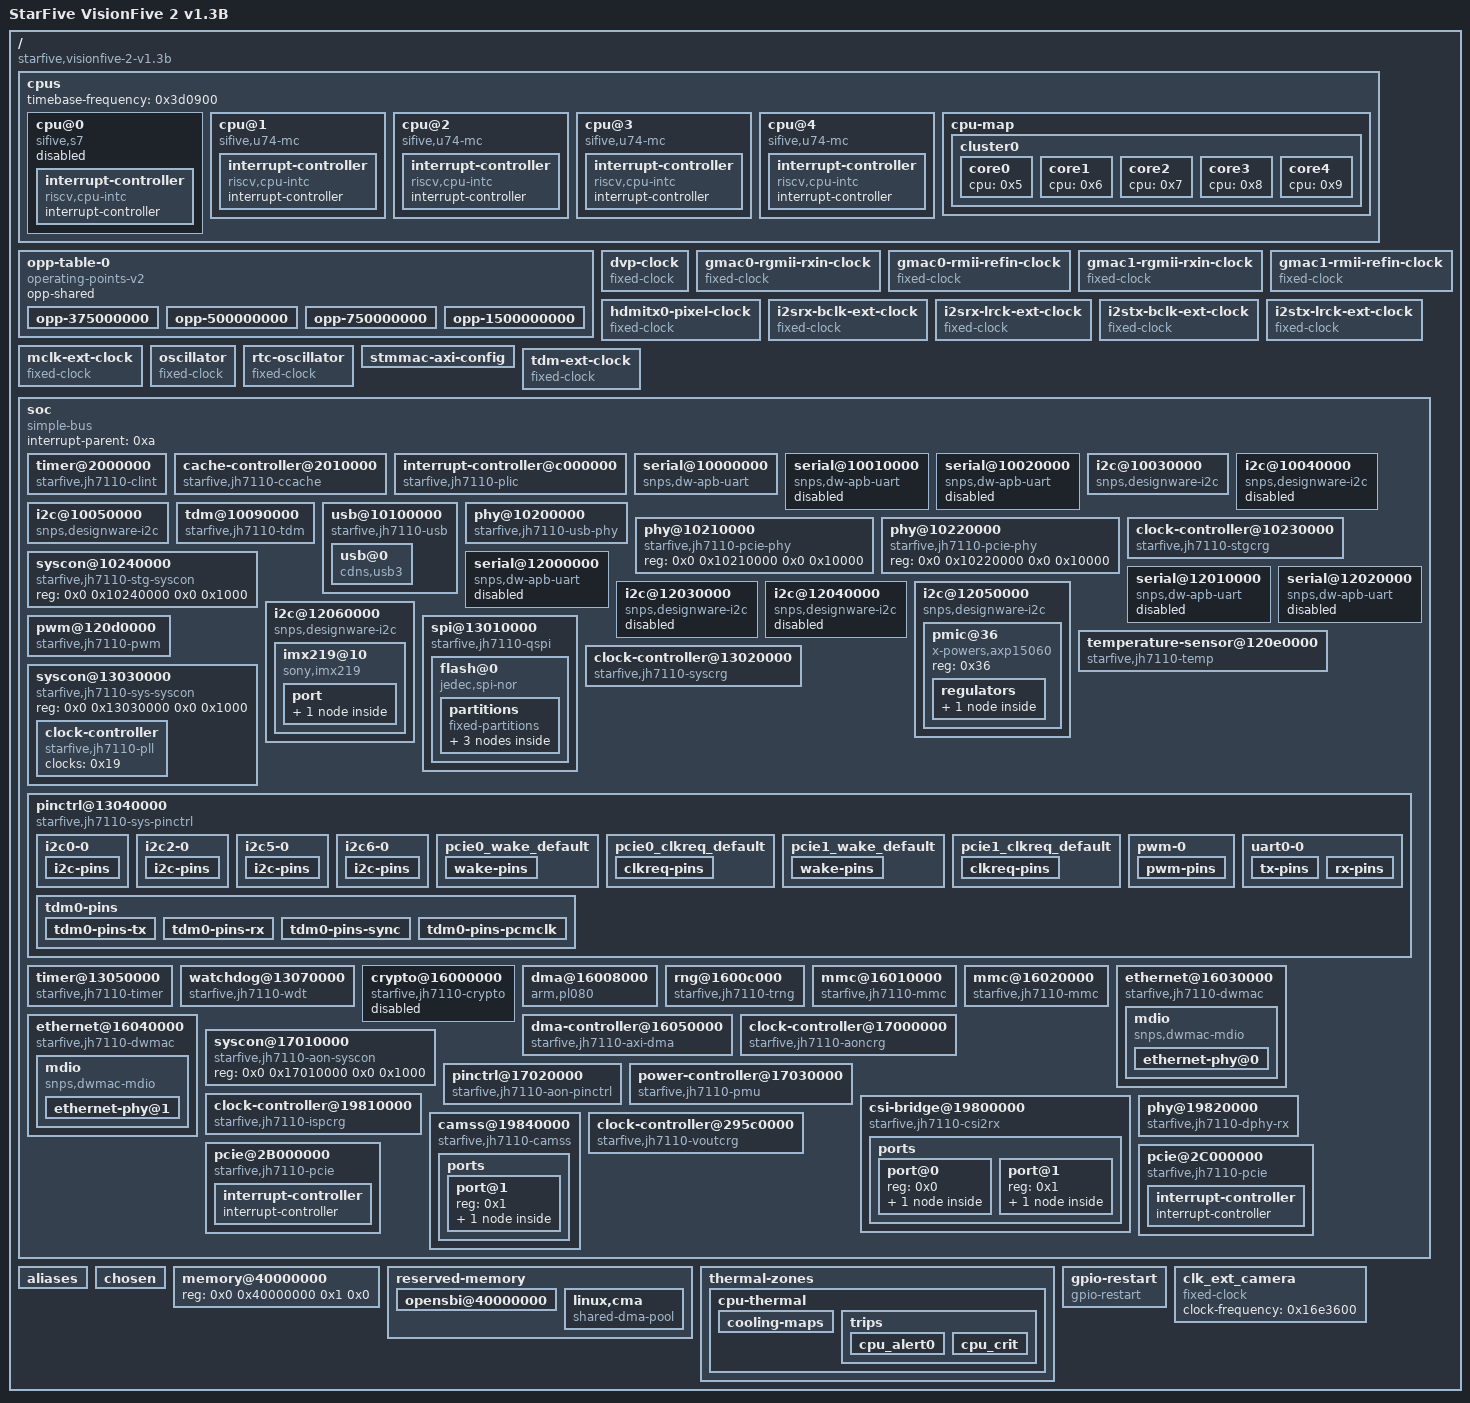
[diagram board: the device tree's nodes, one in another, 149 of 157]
/dts-v1/;

/  {

        serial-number = "VF7110B1-2253-D008E000-00003992";
        compatible = "starfive,visionfive-2-v1.3b", "starfive,jh7110";
        #address-cells = <0x2>;
        #size-cells = <0x2>;
        model = "StarFive VisionFive 2 v1.3B";
        cpus {

                #address-cells = <0x1>;
                #size-cells = <0x0>;
                timebase-frequency = <0x3d0900>;
                cpu@0 {

                        compatible = "sifive,s7", "riscv";
                        reg = <0x0>;
                        device_type = "cpu";
                        i-cache-block-size = <0x40>;
                        i-cache-sets = <0x40>;
                        i-cache-size = <0x4000>;
                        next-level-cache = <0x1>;
                        riscv,isa = "rv64imac_zba_zbb";
                        status = "disabled";
                        phandle = <0x5>;
                        interrupt-controller {

                                compatible = "riscv,cpu-intc";
                                interrupt-controller;
                                #interrupt-cells = <0x1>;
                                phandle = <0xb>;
                        };
                };
                cpu@1 {

                        compatible = "sifive,u74-mc", "riscv";
                        reg = <0x1>;
                        d-cache-block-size = <0x40>;
                        d-cache-sets = <0x40>;
                        d-cache-size = <0x8000>;
                        d-tlb-sets = <0x1>;
                        d-tlb-size = <0x28>;
                        device_type = "cpu";
                        i-cache-block-size = <0x40>;
                        i-cache-sets = <0x40>;
                        i-cache-size = <0x8000>;
                        i-tlb-sets = <0x1>;
                        i-tlb-size = <0x28>;
                        mmu-type = "riscv,sv39";
                        next-level-cache = <0x1>;
                        riscv,isa = "rv64imafdc_zba_zbb";
                        tlb-split;
                        operating-points-v2 = <0x2>;
                        clocks = <0x3 0x1>;
                        clock-names = "cpu";
                        cpu-supply = <0x4>;
                        phandle = <0x6>;
                        interrupt-controller {

                                compatible = "riscv,cpu-intc";
                                interrupt-controller;
                                #interrupt-cells = <0x1>;
                                phandle = <0xc>;
                        };
                };
                cpu@2 {

                        compatible = "sifive,u74-mc", "riscv";
                        reg = <0x2>;
                        d-cache-block-size = <0x40>;
                        d-cache-sets = <0x40>;
                        d-cache-size = <0x8000>;
                        d-tlb-sets = <0x1>;
                        d-tlb-size = <0x28>;
                        device_type = "cpu";
                        i-cache-block-size = <0x40>;
                        i-cache-sets = <0x40>;
                        i-cache-size = <0x8000>;
                        i-tlb-sets = <0x1>;
                        i-tlb-size = <0x28>;
                        mmu-type = "riscv,sv39";
                        next-level-cache = <0x1>;
                        riscv,isa = "rv64imafdc_zba_zbb";
                        tlb-split;
                        operating-points-v2 = <0x2>;
                        clocks = <0x3 0x1>;
                        clock-names = "cpu";
                        cpu-supply = <0x4>;
                        phandle = <0x7>;
                        interrupt-controller {

                                compatible = "riscv,cpu-intc";
                                interrupt-controller;
                                #interrupt-cells = <0x1>;
                                phandle = <0xd>;
                        };
                };
                cpu@3 {

                        compatible = "sifive,u74-mc", "riscv";
                        reg = <0x3>;
                        d-cache-block-size = <0x40>;
                        d-cache-sets = <0x40>;
                        d-cache-size = <0x8000>;
                        d-tlb-sets = <0x1>;
                        d-tlb-size = <0x28>;
                        device_type = "cpu";
                        i-cache-block-size = <0x40>;
                        i-cache-sets = <0x40>;
                        i-cache-size = <0x8000>;
                        i-tlb-sets = <0x1>;
                        i-tlb-size = <0x28>;
                        mmu-type = "riscv,sv39";
                        next-level-cache = <0x1>;
                        riscv,isa = "rv64imafdc_zba_zbb";
                        tlb-split;
                        operating-points-v2 = <0x2>;
                        clocks = <0x3 0x1>;
                        clock-names = "cpu";
                        cpu-supply = <0x4>;
                        phandle = <0x8>;
                        interrupt-controller {

                                compatible = "riscv,cpu-intc";
                                interrupt-controller;
                                #interrupt-cells = <0x1>;
                                phandle = <0xe>;
                        };
                };
                cpu@4 {

                        compatible = "sifive,u74-mc", "riscv";
                        reg = <0x4>;
                        d-cache-block-size = <0x40>;
                        d-cache-sets = <0x40>;
                        d-cache-size = <0x8000>;
                        d-tlb-sets = <0x1>;
                        d-tlb-size = <0x28>;
                        device_type = "cpu";
                        i-cache-block-size = <0x40>;
                        i-cache-sets = <0x40>;
                        i-cache-size = <0x8000>;
                        i-tlb-sets = <0x1>;
                        i-tlb-size = <0x28>;
                        mmu-type = "riscv,sv39";
                        next-level-cache = <0x1>;
                        riscv,isa = "rv64imafdc_zba_zbb";
                        tlb-split;
                        operating-points-v2 = <0x2>;
                        clocks = <0x3 0x1>;
                        clock-names = "cpu";
                        cpu-supply = <0x4>;
                        phandle = <0x9>;
                        interrupt-controller {

                                compatible = "riscv,cpu-intc";
                                interrupt-controller;
                                #interrupt-cells = <0x1>;
                                phandle = <0xf>;
                        };
                };
                cpu-map {

                        cluster0 {

                                core0 {

                                        cpu = <0x5>;
                                };
                                core1 {

                                        cpu = <0x6>;
                                };
                                core2 {

                                        cpu = <0x7>;
                                };
                                core3 {

                                        cpu = <0x8>;
                                };
                                core4 {

                                        cpu = <0x9>;
                                };
                        };
                };
        };
        opp-table-0 {

                compatible = "operating-points-v2";
                opp-shared;
                phandle = <0x2>;
                opp-375000000 {

                        opp-hz = <0x0 0x165a0bc0>;
                        opp-microvolt = <0xc3500>;
                };
                opp-500000000 {

                        opp-hz = <0x0 0x1dcd6500>;
                        opp-microvolt = <0xc3500>;
                };
                opp-750000000 {

                        opp-hz = <0x0 0x2cb41780>;
                        opp-microvolt = <0xc3500>;
                };
                opp-1500000000 {

                        opp-hz = <0x0 0x59682f00>;
                        opp-microvolt = <0xfde80>;
                };
        };
        dvp-clock {

                compatible = "fixed-clock";
                clock-output-names = "dvp_clk";
                #clock-cells = <0x0>;
                clock-frequency = <0x46cf710>;
                phandle = <0x36>;
        };
        gmac0-rgmii-rxin-clock {

                compatible = "fixed-clock";
                clock-output-names = "gmac0_rgmii_rxin";
                #clock-cells = <0x0>;
                clock-frequency = <0x7735940>;
                phandle = <0x30>;
        };
        gmac0-rmii-refin-clock {

                compatible = "fixed-clock";
                clock-output-names = "gmac0_rmii_refin";
                #clock-cells = <0x0>;
                clock-frequency = <0x2faf080>;
                phandle = <0x2f>;
        };
        gmac1-rgmii-rxin-clock {

                compatible = "fixed-clock";
                clock-output-names = "gmac1_rgmii_rxin";
                #clock-cells = <0x0>;
                clock-frequency = <0x7735940>;
                phandle = <0x21>;
        };
        gmac1-rmii-refin-clock {

                compatible = "fixed-clock";
                clock-output-names = "gmac1_rmii_refin";
                #clock-cells = <0x0>;
                clock-frequency = <0x2faf080>;
                phandle = <0x20>;
        };
        hdmitx0-pixel-clock {

                compatible = "fixed-clock";
                clock-output-names = "hdmitx0_pixelclk";
                #clock-cells = <0x0>;
                clock-frequency = <0x11b3dc40>;
                phandle = <0x39>;
        };
        i2srx-bclk-ext-clock {

                compatible = "fixed-clock";
                clock-output-names = "i2srx_bclk_ext";
                #clock-cells = <0x0>;
                clock-frequency = <0xbb8000>;
                phandle = <0x24>;
        };
        i2srx-lrck-ext-clock {

                compatible = "fixed-clock";
                clock-output-names = "i2srx_lrck_ext";
                #clock-cells = <0x0>;
                clock-frequency = <0x2ee00>;
                phandle = <0x25>;
        };
        i2stx-bclk-ext-clock {

                compatible = "fixed-clock";
                clock-output-names = "i2stx_bclk_ext";
                #clock-cells = <0x0>;
                clock-frequency = <0xbb8000>;
                phandle = <0x22>;
        };
        i2stx-lrck-ext-clock {

                compatible = "fixed-clock";
                clock-output-names = "i2stx_lrck_ext";
                #clock-cells = <0x0>;
                clock-frequency = <0x2ee00>;
                phandle = <0x23>;
        };
        mclk-ext-clock {

                compatible = "fixed-clock";
                clock-output-names = "mclk_ext";
                #clock-cells = <0x0>;
                clock-frequency = <0xbb8000>;
                phandle = <0x26>;
        };
        oscillator {

                compatible = "fixed-clock";
                clock-output-names = "osc";
                #clock-cells = <0x0>;
                clock-frequency = <0x16e3600>;
                phandle = <0x19>;
        };
        rtc-oscillator {

                compatible = "fixed-clock";
                clock-output-names = "rtc_osc";
                #clock-cells = <0x0>;
                clock-frequency = <0x8000>;
                phandle = <0x31>;
        };
        stmmac-axi-config {

                snps,lpi_en;
                snps,wr_osr_lmt = <0x4>;
                snps,rd_osr_lmt = <0x4>;
                snps,blen = <0x100 0x80 0x40 0x20 0x0 0x0 0x0>;
                phandle = <0x2b>;
        };
        tdm-ext-clock {

                compatible = "fixed-clock";
                clock-output-names = "tdm_ext";
                #clock-cells = <0x0>;
                clock-frequency = <0x2ee0000>;
                phandle = <0x13>;
        };
        soc {

                compatible = "simple-bus";
                interrupt-parent = <0xa>;
                #address-cells = <0x2>;
                #size-cells = <0x2>;
                ranges;
                timer@2000000 {

                        compatible = "starfive,jh7110-clint", "sifive,clint0";
                        reg = <0x0 0x2000000 0x0 0x10000>;
                        interrupts-extended = <0xb 0x3 0xb 0x7 0xc 0x3 0xc 0x7 0xd 0x3 0xd 0x7 0xe 0x3 0xe 0x7 0xf 0x3 0xf 0x7>;
                };
                cache-controller@2010000 {

                        compatible = "starfive,jh7110-ccache", "sifive,ccache0", "cache";
                        reg = <0x0 0x2010000 0x0 0x4000>;
                        interrupts = <0x1 0x3 0x4 0x2>;
                        cache-block-size = <0x40>;
                        cache-level = <0x2>;
                        cache-sets = <0x800>;
                        cache-size = <0x200000>;
                        cache-unified;
                        phandle = <0x1>;
                };
                interrupt-controller@c000000 {

                        compatible = "starfive,jh7110-plic", "sifive,plic-1.0.0";
                        reg = <0x0 0xc000000 0x0 0x4000000>;
                        interrupts-extended = <0xb 0xb 0xc 0xb 0xc 0x9 0xd 0xb 0xd 0x9 0xe 0xb 0xe 0x9 0xf 0xb 0xf 0x9>;
                        interrupt-controller;
                        #interrupt-cells = <0x1>;
                        #address-cells = <0x0>;
                        riscv,ndev = <0x88>;
                        phandle = <0xa>;
                };
                serial@10000000 {

                        compatible = "snps,dw-apb-uart";
                        reg = <0x0 0x10000000 0x0 0x10000>;
                        clocks = <0x3 0x92 0x3 0x91>;
                        clock-names = "baudclk", "apb_pclk";
                        resets = <0x3 0x53>;
                        interrupts = <0x20>;
                        reg-io-width = <0x4>;
                        reg-shift = <0x2>;
                        status = "okay";
                        pinctrl-names = "default";
                        pinctrl-0 = <0x10>;
                };
                serial@10010000 {

                        compatible = "snps,dw-apb-uart";
                        reg = <0x0 0x10010000 0x0 0x10000>;
                        clocks = <0x3 0x94 0x3 0x93>;
                        clock-names = "baudclk", "apb_pclk";
                        resets = <0x3 0x55>;
                        interrupts = <0x21>;
                        reg-io-width = <0x4>;
                        reg-shift = <0x2>;
                        status = "disabled";
                };
                serial@10020000 {

                        compatible = "snps,dw-apb-uart";
                        reg = <0x0 0x10020000 0x0 0x10000>;
                        clocks = <0x3 0x96 0x3 0x95>;
                        clock-names = "baudclk", "apb_pclk";
                        resets = <0x3 0x57>;
                        interrupts = <0x22>;
                        reg-io-width = <0x4>;
                        reg-shift = <0x2>;
                        status = "disabled";
                };
                i2c@10030000 {

                        compatible = "snps,designware-i2c";
                        reg = <0x0 0x10030000 0x0 0x10000>;
                        clocks = <0x3 0x8a>;
                        clock-names = "ref";
                        resets = <0x3 0x4c>;
                        interrupts = <0x23>;
                        #address-cells = <0x1>;
                        #size-cells = <0x0>;
                        status = "okay";
                        clock-frequency = <0x186a0>;
                        i2c-sda-hold-time-ns = <0x12c>;
                        i2c-sda-falling-time-ns = <0x1fe>;
                        i2c-scl-falling-time-ns = <0x1fe>;
                        pinctrl-names = "default";
                        pinctrl-0 = <0x11>;
                };
                i2c@10040000 {

                        compatible = "snps,designware-i2c";
                        reg = <0x0 0x10040000 0x0 0x10000>;
                        clocks = <0x3 0x8b>;
                        clock-names = "ref";
                        resets = <0x3 0x4d>;
                        interrupts = <0x24>;
                        #address-cells = <0x1>;
                        #size-cells = <0x0>;
                        status = "disabled";
                };
                i2c@10050000 {

                        compatible = "snps,designware-i2c";
                        reg = <0x0 0x10050000 0x0 0x10000>;
                        clocks = <0x3 0x8c>;
                        clock-names = "ref";
                        resets = <0x3 0x4e>;
                        interrupts = <0x25>;
                        #address-cells = <0x1>;
                        #size-cells = <0x0>;
                        status = "okay";
                        clock-frequency = <0x186a0>;
                        i2c-sda-hold-time-ns = <0x12c>;
                        i2c-sda-falling-time-ns = <0x1fe>;
                        i2c-scl-falling-time-ns = <0x1fe>;
                        pinctrl-names = "default";
                        pinctrl-0 = <0x12>;
                };
                tdm@10090000 {

                        compatible = "starfive,jh7110-tdm";
                        reg = <0x0 0x10090000 0x0 0x1000>;
                        clocks = <0x3 0xb8 0x3 0xb9 0x3 0xba 0x3 0xbb 0x3 0x11 0x13>;
                        clock-names = "tdm_ahb", "tdm_apb", "tdm_internal", "tdm", "mclk_inner", "tdm_ext";
                        resets = <0x3 0x69 0x3 0x6b 0x3 0x6a>;
                        dmas = <0x14 0x14 0x14 0x15>;
                        dma-names = "rx", "tx";
                        #sound-dai-cells = <0x0>;
                        status = "okay";
                        pinctrl-names = "default";
                        pinctrl-0 = <0x15>;
                };
                usb@10100000 {

                        compatible = "starfive,jh7110-usb";
                        ranges = <0x0 0x0 0x10100000 0x100000>;
                        #address-cells = <0x1>;
                        #size-cells = <0x1>;
                        starfive,stg-syscon = <0x16 0x4>;
                        clocks = <0x17 0x4 0x17 0x5 0x17 0x1 0x17 0x3 0x17 0x2>;
                        clock-names = "lpm", "stb", "apb", "axi", "utmi_apb";
                        resets = <0x17 0xa 0x17 0x8 0x17 0x7 0x17 0x9>;
                        reset-names = "pwrup", "apb", "axi", "utmi_apb";
                        status = "okay";
                        dr_mode = "peripheral";
                        usb@0 {

                                compatible = "cdns,usb3";
                                reg = <0x0 0x10000 0x10000 0x10000 0x20000 0x10000>;
                                reg-names = "otg", "xhci", "dev";
                                interrupts = <0x64 0x6c 0x6e>;
                                interrupt-names = "host", "peripheral", "otg";
                                phys = <0x18>;
                                phy-names = "cdns3,usb2-phy";
                        };
                };
                phy@10200000 {

                        compatible = "starfive,jh7110-usb-phy";
                        reg = <0x0 0x10200000 0x0 0x10000>;
                        clocks = <0x3 0x5f 0x17 0x6>;
                        clock-names = "125m", "app_125m";
                        #phy-cells = <0x0>;
                        phandle = <0x18>;
                };
                phy@10210000 {

                        compatible = "starfive,jh7110-pcie-phy";
                        reg = <0x0 0x10210000 0x0 0x10000>;
                        #phy-cells = <0x0>;
                        phandle = <0x3c>;
                };
                phy@10220000 {

                        compatible = "starfive,jh7110-pcie-phy";
                        reg = <0x0 0x10220000 0x0 0x10000>;
                        #phy-cells = <0x0>;
                        phandle = <0x3f>;
                };
                clock-controller@10230000 {

                        compatible = "starfive,jh7110-stgcrg";
                        reg = <0x0 0x10230000 0x0 0x10000>;
                        clocks = <0x19 0x3 0x36 0x3 0x8 0x3 0x5f 0x3 0x2 0x3 0x37 0x3 0x6 0x3 0xb>;
                        clock-names = "osc", "hifi4_core", "stg_axiahb", "usb_125m", "cpu_bus", "hifi4_axi", "nocstg_bus", "apb_bus";
                        #clock-cells = <0x1>;
                        #reset-cells = <0x1>;
                        phandle = <0x17>;
                };
                syscon@10240000 {

                        compatible = "starfive,jh7110-stg-syscon", "syscon";
                        reg = <0x0 0x10240000 0x0 0x1000>;
                        phandle = <0x16>;
                };
                serial@12000000 {

                        compatible = "snps,dw-apb-uart";
                        reg = <0x0 0x12000000 0x0 0x10000>;
                        clocks = <0x3 0x98 0x3 0x97>;
                        clock-names = "baudclk", "apb_pclk";
                        resets = <0x3 0x59>;
                        interrupts = <0x2d>;
                        reg-io-width = <0x4>;
                        reg-shift = <0x2>;
                        status = "disabled";
                };
                serial@12010000 {

                        compatible = "snps,dw-apb-uart";
                        reg = <0x0 0x12010000 0x0 0x10000>;
                        clocks = <0x3 0x9a 0x3 0x99>;
                        clock-names = "baudclk", "apb_pclk";
                        resets = <0x3 0x5b>;
                        interrupts = <0x2e>;
                        reg-io-width = <0x4>;
                        reg-shift = <0x2>;
                        status = "disabled";
                };
                serial@12020000 {

                        compatible = "snps,dw-apb-uart";
                        reg = <0x0 0x12020000 0x0 0x10000>;
                        clocks = <0x3 0x9c 0x3 0x9b>;
                        clock-names = "baudclk", "apb_pclk";
                        resets = <0x3 0x5d>;
                        interrupts = <0x2f>;
                        reg-io-width = <0x4>;
                        reg-shift = <0x2>;
                        status = "disabled";
                };
                i2c@12030000 {

                        compatible = "snps,designware-i2c";
                        reg = <0x0 0x12030000 0x0 0x10000>;
                        clocks = <0x3 0x8d>;
                        clock-names = "ref";
                        resets = <0x3 0x4f>;
                        interrupts = <0x30>;
                        #address-cells = <0x1>;
                        #size-cells = <0x0>;
                        status = "disabled";
                };
                i2c@12040000 {

                        compatible = "snps,designware-i2c";
                        reg = <0x0 0x12040000 0x0 0x10000>;
                        clocks = <0x3 0x8e>;
                        clock-names = "ref";
                        resets = <0x3 0x50>;
                        interrupts = <0x31>;
                        #address-cells = <0x1>;
                        #size-cells = <0x0>;
                        status = "disabled";
                };
                i2c@12050000 {

                        compatible = "snps,designware-i2c";
                        reg = <0x0 0x12050000 0x0 0x10000>;
                        clocks = <0x3 0x8f>;
                        clock-names = "ref";
                        resets = <0x3 0x51>;
                        interrupts = <0x32>;
                        #address-cells = <0x1>;
                        #size-cells = <0x0>;
                        status = "okay";
                        clock-frequency = <0x186a0>;
                        i2c-sda-hold-time-ns = <0x12c>;
                        i2c-sda-falling-time-ns = <0x1fe>;
                        i2c-scl-falling-time-ns = <0x1fe>;
                        pinctrl-names = "default";
                        pinctrl-0 = <0x1a>;
                        pmic@36 {

                                compatible = "x-powers,axp15060";
                                reg = <0x36>;
                                regulators {

                                        dcdc2 {

                                                regulator-always-on;
                                                regulator-min-microvolt = <0x7a120>;
                                                regulator-max-microvolt = <0x177fa0>;
                                                regulator-name = "vdd-cpu";
                                                phandle = <0x4>;
                                        };
                                };
                        };
                };
                i2c@12060000 {

                        compatible = "snps,designware-i2c";
                        reg = <0x0 0x12060000 0x0 0x10000>;
                        clocks = <0x3 0x90>;
                        clock-names = "ref";
                        resets = <0x3 0x52>;
                        interrupts = <0x33>;
                        #address-cells = <0x1>;
                        #size-cells = <0x0>;
                        status = "okay";
                        clock-frequency = <0x186a0>;
                        i2c-sda-hold-time-ns = <0x12c>;
                        i2c-sda-falling-time-ns = <0x1fe>;
                        i2c-scl-falling-time-ns = <0x1fe>;
                        pinctrl-names = "default";
                        pinctrl-0 = <0x1b>;
                        imx219@10 {

                                compatible = "sony,imx219";
                                reg = <0x10>;
                                clocks = <0x1c>;
                                reset-gpio = <0x1d 0x12 0x0>;
                                rotation = <0x0>;
                                orientation = <0x1>;
                                port {

                                        endpoint {

                                                remote-endpoint = <0x1e>;
                                                bus-type = <0x4>;
                                                clock-lanes = <0x0>;
                                                data-lanes = <0x1 0x2>;
                                                link-frequencies = <0x0 0x1b2e0200>;
                                                phandle = <0x34>;
                                        };
                                };
                        };
                };
                pwm@120d0000 {

                        compatible = "starfive,jh7110-pwm";
                        reg = <0x0 0x120d0000 0x0 0x10000>;
                        clocks = <0x3 0x79>;
                        resets = <0x3 0x6c>;
                        #pwm-cells = <0x3>;
                        status = "okay";
                        pinctrl-names = "default";
                        pinctrl-0 = <0x1f>;
                };
                temperature-sensor@120e0000 {

                        compatible = "starfive,jh7110-temp";
                        reg = <0x0 0x120e0000 0x0 0x10000>;
                        clocks = <0x3 0x82 0x3 0x81>;
                        clock-names = "sense", "bus";
                        resets = <0x3 0x7c 0x3 0x7b>;
                        reset-names = "sense", "bus";
                        #thermal-sensor-cells = <0x0>;
                        phandle = <0x40>;
                };
                spi@13010000 {

                        compatible = "starfive,jh7110-qspi", "cdns,qspi-nor";
                        reg = <0x0 0x13010000 0x0 0x10000 0x0 0x21000000 0x0 0x400000>;
                        interrupts = <0x19>;
                        clocks = <0x3 0x5a 0x3 0x57 0x3 0x58>;
                        clock-names = "qspi-ref", "qspi-ahb", "qspi-apb";
                        resets = <0x3 0x3e 0x3 0x3d 0x3 0x3f>;
                        reset-names = "qspi", "qspi-ocp", "rstc_ref";
                        cdns,fifo-depth = <0x100>;
                        cdns,fifo-width = <0x4>;
                        cdns,trigger-address = <0x0>;
                        #address-cells = <0x1>;
                        #size-cells = <0x0>;
                        flash@0 {

                                compatible = "jedec,spi-nor";
                                reg = <0x0>;
                                cdns,read-delay = <0x5>;
                                spi-max-frequency = <0xb71b00>;
                                cdns,tshsl-ns = <0x1>;
                                cdns,tsd2d-ns = <0x1>;
                                cdns,tchsh-ns = <0x1>;
                                cdns,tslch-ns = <0x1>;
                                partitions {

                                        compatible = "fixed-partitions";
                                        #address-cells = <0x1>;
                                        #size-cells = <0x1>;
                                        spl@0 {

                                                reg = <0x0 0x20000>;
                                        };
                                        uboot@100000 {

                                                reg = <0x100000 0x300000>;
                                        };
                                        data@f00000 {

                                                reg = <0xf00000 0x100000>;
                                        };
                                };
                        };
                };
                clock-controller@13020000 {

                        compatible = "starfive,jh7110-syscrg";
                        reg = <0x0 0x13020000 0x0 0x10000>;
                        clocks = <0x19 0x20 0x21 0x22 0x23 0x24 0x25 0x13 0x26 0x27 0x0 0x27 0x1 0x27 0x2>;
                        clock-names = "osc", "gmac1_rmii_refin", "gmac1_rgmii_rxin", "i2stx_bclk_ext", "i2stx_lrck_ext", "i2srx_bclk_ext", "i2srx_lrck_ext", 
"tdm_ext", "mclk_ext", "pll0_out", "pll1_out", "pll2_out";
                        #clock-cells = <0x1>;
                        #reset-cells = <0x1>;
                        phandle = <0x3>;
                };
                syscon@13030000 {

                        compatible = "starfive,jh7110-sys-syscon", "syscon", "simple-mfd";
                        reg = <0x0 0x13030000 0x0 0x1000>;
                        phandle = <0x29>;
                        clock-controller {

                                compatible = "starfive,jh7110-pll";
                                clocks = <0x19>;
                                #clock-cells = <0x1>;
                                phandle = <0x27>;
                        };
                };
                pinctrl@13040000 {

                        compatible = "starfive,jh7110-sys-pinctrl";
                        reg = <0x0 0x13040000 0x0 0x10000>;
                        clocks = <0x3 0x70>;
                        resets = <0x3 0x2>;
                        interrupts = <0x56>;
                        interrupt-controller;
                        #interrupt-cells = <0x2>;
                        gpio-controller;
                        #gpio-cells = <0x2>;
                        phandle = <0x1d>;
                        i2c0-0 {

                                phandle = <0x11>;
                                i2c-pins {

                                        pinmux = <0x9001439 0xa00183a>;
                                        bias-disable;
                                        input-enable;
                                        input-schmitt-enable;
                                };
                        };
                        i2c2-0 {

                                phandle = <0x12>;
                                i2c-pins {

                                        pinmux = <0x3b007803 0x3c007c02>;
                                        bias-disable;
                                        input-enable;
                                        input-schmitt-enable;
                                };
                        };
                        i2c5-0 {

                                phandle = <0x1a>;
                                i2c-pins {

                                        pinmux = <0x4f00a813 0x5000ac14>;
                                        bias-disable;
                                        input-enable;
                                        input-schmitt-enable;
                                };
                        };
                        i2c6-0 {

                                phandle = <0x1b>;
                                i2c-pins {

                                        pinmux = <0x5600b810 0x5700bc11>;
                                        bias-disable;
                                        input-enable;
                                        input-schmitt-enable;
                                };
                        };
                        pcie0_wake_default {

                                wake-pins {

                                        pinmux = <0xff010020>;
                                        bias-disable;
                                        drive-strength = <0x2>;
                                        input-enable;
                                        input-schmitt-disable;
                                        slew-rate = <0x0>;
                                };
                        };
                        pcie0_clkreq_default {

                                clkreq-pins {

                                        bias-disable;
                                        pinmux = <0xff01001b>;
                                        drive-strength = <0x2>;
                                        input-enable;
                                        input-schmitt-disable;
                                        slew-rate = <0x0>;
                                };
                        };
                        pcie1_wake_default {

                                wake-pins {

                                        bias-disable;
                                        pinmux = <0xff010015>;
                                        drive-strength = <0x2>;
                                        input-enable;
                                        input-schmitt-disable;
                                        slew-rate = <0x0>;
                                };
                        };
                        pcie1_clkreq_default {

                                clkreq-pins {

                                        bias-disable;
                                        pinmux = <0xff01001d>;
                                        drive-strength = <0x2>;
                                        input-enable;
                                        input-schmitt-disable;
                                        slew-rate = <0x0>;
                                };
                        };
                        pwm-0 {

                                phandle = <0x1f>;
                                pwm-pins {

                                        pinmux = <0xff18242e 0xff19283b>;
                                        bias-disable;
                                        drive-strength = <0xc>;
                                        input-disable;
                                        input-schmitt-disable;
                                        slew-rate = <0x0>;
                                };
                        };
                        tdm0-pins {

                                phandle = <0x15>;
                                tdm0-pins-tx {

                                        pinmux = <0xff29002c>;
                                        bias-pull-up;
                                        drive-strength = <0x2>;
                                        input-disable;
                                        input-schmitt-disable;
                                        slew-rate = <0x0>;
                                };
                                tdm0-pins-rx {

                                        pinmux = <0x2401043d>;
                                        input-enable;
                                };
                                tdm0-pins-sync {

                                        pinmux = <0x2501043f>;
                                        input-enable;
                                };
                                tdm0-pins-pcmclk {

                                        pinmux = <0x23010426>;
                                        input-enable;
                                };
                        };
                        uart0-0 {

                                phandle = <0x10>;
                                tx-pins {

                                        pinmux = <0xff140005>;
                                        bias-disable;
                                        drive-strength = <0xc>;
                                        input-disable;
                                        input-schmitt-disable;
                                        slew-rate = <0x0>;
                                };
                                rx-pins {

                                        pinmux = <0xe000406>;
                                        bias-disable;
                                        drive-strength = <0x2>;
                                        input-enable;
                                        input-schmitt-enable;
                                        slew-rate = <0x0>;
                                };
                        };
                };
                timer@13050000 {

                        compatible = "starfive,jh7110-timer";
                        reg = <0x0 0x13050000 0x0 0x10000>;
                        interrupts = <0x45 0x46 0x47 0x48>;
                        clocks = <0x3 0x7c 0x3 0x7d 0x3 0x7e 0x3 0x7f 0x3 0x80>;
                        clock-names = "apb", "ch0", "ch1", "ch2", "ch3";
                        resets = <0x3 0x75 0x3 0x76 0x3 0x77 0x3 0x78 0x3 0x79>;
                        reset-names = "apb", "ch0", "ch1", "ch2", "ch3";
                };
                watchdog@13070000 {

                        compatible = "starfive,jh7110-wdt";
                        reg = <0x0 0x13070000 0x0 0x10000>;
                        clocks = <0x3 0x7a 0x3 0x7b>;
                        clock-names = "apb", "core";
                        resets = <0x3 0x6d 0x3 0x6e>;
                };
                crypto@16000000 {

                        compatible = "starfive,jh7110-crypto";
                        reg = <0x0 0x16000000 0x0 0x4000>;
                        clocks = <0x17 0xf 0x17 0x10>;
                        clock-names = "hclk", "ahb";
                        interrupts = <0x1c>;
                        resets = <0x17 0x3>;
                        dmas = <0x28 0x1 0x2 0x28 0x0 0x2>;
                        dma-names = "tx", "rx";
                        status = "disabled";
                };
                dma@16008000 {

                        compatible = "arm,pl080", "arm,primecell";
                        arm,primecell-periphid = <0x41080>;
                        reg = <0x0 0x16008000 0x0 0x4000>;
                        interrupts = <0x1d>;
                        clocks = <0x17 0xf 0x17 0x10>;
                        clock-names = "hclk", "apb_pclk";
                        resets = <0x17 0x3>;
                        lli-bus-interface-ahb1;
                        mem-bus-interface-ahb1;
                        memcpy-burst-size = <0x100>;
                        memcpy-bus-width = <0x20>;
                        #dma-cells = <0x2>;
                        phandle = <0x28>;
                };
                rng@1600c000 {

                        compatible = "starfive,jh7110-trng";
                        reg = <0x0 0x1600c000 0x0 0x4000>;
                        clocks = <0x17 0xf 0x17 0x10>;
                        clock-names = "hclk", "ahb";
                        resets = <0x17 0x3>;
                        interrupts = <0x1e>;
                };
                mmc@16010000 {

                        compatible = "starfive,jh7110-mmc";
                        reg = <0x0 0x16010000 0x0 0x10000>;
                        clocks = <0x3 0x5b 0x3 0x5d>;
                        clock-names = "biu", "ciu";
                        resets = <0x3 0x40>;
                        reset-names = "reset";
                        interrupts = <0x4a>;
                        fifo-depth = <0x20>;
                        fifo-watermark-aligned;
                        data-addr = <0x0>;
                        starfive,sysreg = <0x29 0x14 0x1a 0x7c000000>;
                        status = "okay";
                        max-frequency = <0x5f5e100>;
                        bus-width = <0x8>;
                        cap-mmc-highspeed;
                        mmc-ddr-1_8v;
                        mmc-hs200-1_8v;
                        non-removable;
                        cap-mmc-hw-reset;
                        post-power-on-delay-ms = <0xc8>;
                };
                mmc@16020000 {

                        compatible = "starfive,jh7110-mmc";
                        reg = <0x0 0x16020000 0x0 0x10000>;
                        clocks = <0x3 0x5c 0x3 0x5e>;
                        clock-names = "biu", "ciu";
                        resets = <0x3 0x41>;
                        reset-names = "reset";
                        interrupts = <0x4b>;
                        fifo-depth = <0x20>;
                        fifo-watermark-aligned;
                        data-addr = <0x0>;
                        starfive,sysreg = <0x29 0x9c 0x1 0x3e>;
                        status = "okay";
                        max-frequency = <0x5f5e100>;
                        bus-width = <0x4>;
                        no-sdio;
                        no-mmc;
                        broken-cd;
                        cap-sd-highspeed;
                        post-power-on-delay-ms = <0xc8>;
                };
                ethernet@16030000 {

                        local-mac-address = [6c cf 39 00 42 8c];
                        compatible = "starfive,jh7110-dwmac", "snps,dwmac-5.20";
                        reg = <0x0 0x16030000 0x0 0x10000>;
                        clocks = <0x2a 0x3 0x2a 0x2 0x3 0x6d 0x2a 0x6 0x3 0x6f>;
                        clock-names = "stmmaceth", "pclk", "ptp_ref", "tx", "gtx";
                        resets = <0x2a 0x0 0x2a 0x1>;
                        reset-names = "stmmaceth", "ahb";
                        interrupts = <0x7 0x6 0x5>;
                        interrupt-names = "macirq", "eth_wake_irq", "eth_lpi";
                        rx-fifo-depth = <0x800>;
                        tx-fifo-depth = <0x800>;
                        snps,multicast-filter-bins = <0x40>;
                        snps,perfect-filter-entries = <0x8>;
                        snps,fixed-burst;
                        snps,no-pbl-x8;
                        snps,force_thresh_dma_mode;
                        snps,axi-config = <0x2b>;
                        snps,tso;
                        snps,en-tx-lpi-clockgating;
                        snps,txpbl = <0x10>;
                        snps,rxpbl = <0x10>;
                        starfive,syscon = <0x2c 0xc 0x12>;
                        status = "okay";
                        phy-handle = <0x2d>;
                        phy-mode = "rgmii-id";
                        starfive,tx-use-rgmii-clk;
                        assigned-clocks = <0x2a 0x5>;
                        assigned-clock-parents = <0x2a 0x4>;
                        mdio {

                                #address-cells = <0x1>;
                                #size-cells = <0x0>;
                                compatible = "snps,dwmac-mdio";
                                ethernet-phy@0 {

                                        reg = <0x0>;
                                        motorcomm,tx-clk-adj-enabled;
                                        motorcomm,tx-clk-100-inverted;
                                        motorcomm,tx-clk-1000-inverted;
                                        motorcomm,rx-clk-driver-strength = <0x6>;
                                        motorcomm,rx-data-driver-strength = <0x3>;
                                        rx-internal-delay-ps = <0x5dc>;
                                        tx-internal-delay-ps = <0x5dc>;
                                        phandle = <0x2d>;
                                };
                        };
                };
                ethernet@16040000 {

                        local-mac-address = [6c cf 39 00 42 8d];
                        compatible = "starfive,jh7110-dwmac", "snps,dwmac-5.20";
                        reg = <0x0 0x16040000 0x0 0x10000>;
                        clocks = <0x3 0x62 0x3 0x61 0x3 0x66 0x3 0x6a 0x3 0x6b>;
                        clock-names = "stmmaceth", "pclk", "ptp_ref", "tx", "gtx";
                        resets = <0x3 0x42 0x3 0x43>;
                        reset-names = "stmmaceth", "ahb";
                        interrupts = <0x4e 0x4d 0x4c>;
                        interrupt-names = "macirq", "eth_wake_irq", "eth_lpi";
                        rx-fifo-depth = <0x800>;
                        tx-fifo-depth = <0x800>;
                        snps,multicast-filter-bins = <0x40>;
                        snps,perfect-filter-entries = <0x8>;
                        snps,fixed-burst;
                        snps,no-pbl-x8;
                        snps,force_thresh_dma_mode;
                        snps,axi-config = <0x2b>;
                        snps,tso;
                        snps,en-tx-lpi-clockgating;
                        snps,txpbl = <0x10>;
                        snps,rxpbl = <0x10>;
                        starfive,syscon = <0x29 0x90 0x2>;
                        status = "okay";
                        phy-handle = <0x2e>;
                        phy-mode = "rgmii-id";
                        starfive,tx-use-rgmii-clk;
                        assigned-clocks = <0x3 0x69>;
                        assigned-clock-parents = <0x3 0x65>;
                        mdio {

                                #address-cells = <0x1>;
                                #size-cells = <0x0>;
                                compatible = "snps,dwmac-mdio";
                                ethernet-phy@1 {

                                        reg = <0x0>;
                                        motorcomm,tx-clk-adj-enabled;
                                        motorcomm,tx-clk-100-inverted;
                                        motorcomm,rx-clk-driver-strength = <0x6>;
                                        motorcomm,rx-data-driver-strength = <0x3>;
                                        rx-internal-delay-ps = <0x12c>;
                                        tx-internal-delay-ps = <0x0>;
                                        phandle = <0x2e>;
                                };
                        };
                };
                dma-controller@16050000 {

                        compatible = "starfive,jh7110-axi-dma";
                        reg = <0x0 0x16050000 0x0 0x10000>;
                        clocks = <0x17 0x1b 0x17 0x1c>;
                        clock-names = "core-clk", "cfgr-clk";
                        resets = <0x17 0x5 0x17 0x6>;
                        interrupts = <0x49>;
                        #dma-cells = <0x1>;
                        dma-channels = <0x4>;
                        snps,dma-masters = <0x1>;
                        snps,data-width = <0x3>;
                        snps,block-size = <0x10000 0x10000 0x10000 0x10000>;
                        snps,priority = <0x0 0x1 0x2 0x3>;
                        snps,axi-max-burst-len = <0x10>;
                        phandle = <0x14>;
                };
                clock-controller@17000000 {

                        compatible = "starfive,jh7110-aoncrg";
                        reg = <0x0 0x17000000 0x0 0x10000>;
                        clocks = <0x19 0x2f 0x30 0x3 0x8 0x3 0xb 0x3 0x6c 0x31>;
                        clock-names = "osc", "gmac0_rmii_refin", "gmac0_rgmii_rxin", "stg_axiahb", "apb_bus", "gmac0_gtxclk", "rtc_osc";
                        #clock-cells = <0x1>;
                        #reset-cells = <0x1>;
                        phandle = <0x2a>;
                };
                syscon@17010000 {

                        compatible = "starfive,jh7110-aon-syscon", "syscon";
                        reg = <0x0 0x17010000 0x0 0x1000>;
                        #power-domain-cells = <0x1>;
                        phandle = <0x2c>;
                };
                pinctrl@17020000 {

                        compatible = "starfive,jh7110-aon-pinctrl";
                        reg = <0x0 0x17020000 0x0 0x10000>;
                        resets = <0x2a 0x2>;
                        interrupts = <0x55>;
                        interrupt-controller;
                        #interrupt-cells = <0x2>;
                        gpio-controller;
                        #gpio-cells = <0x2>;
                };
                power-controller@17030000 {

                        compatible = "starfive,jh7110-pmu";
                        reg = <0x0 0x17030000 0x0 0x10000>;
                        interrupts = <0x6f>;
                        #power-domain-cells = <0x1>;
                        phandle = <0x37>;
                };
                csi-bridge@19800000 {

                        compatible = "starfive,jh7110-csi2rx";
                        reg = <0x0 0x19800000 0x0 0x10000>;
                        clocks = <0x32 0x7 0x32 0x6 0x32 0x8 0x32 0x9 0x32 0xa 0x32 0xb>;
                        clock-names = "sys_clk", "p_clk", "pixel_if0_clk", "pixel_if1_clk", "pixel_if2_clk", "pixel_if3_clk";
                        resets = <0x32 0x9 0x32 0x4 0x32 0x5 0x32 0x6 0x32 0x7 0x32 0x8>;
                        reset-names = "sys", "reg_bank", "pixel_if0", "pixel_if1", "pixel_if2", "pixel_if3";
                        phys = <0x33>;
                        phy-names = "dphy";
                        status = "okay";
                        assigned-clocks = <0x32 0x7>;
                        assigned-clock-rates = <0x11b3dc40>;
                        ports {

                                #address-cells = <0x1>;
                                #size-cells = <0x0>;
                                port@0 {

                                        reg = <0x0>;
                                        endpoint {

                                                remote-endpoint = <0x34>;
                                                bus-type = <0x4>;
                                                clock-lanes = <0x0>;
                                                data-lanes = <0x1 0x2>;
                                                status = "okay";
                                                phandle = <0x1e>;
                                        };
                                };
                                port@1 {

                                        reg = <0x1>;
                                        endpoint {

                                                remote-endpoint = <0x35>;
                                                status = "okay";
                                                phandle = <0x38>;
                                        };
                                };
                        };
                };
                clock-controller@19810000 {

                        compatible = "starfive,jh7110-ispcrg";
                        reg = <0x0 0x19810000 0x0 0x10000>;
                        clocks = <0x3 0x33 0x3 0x34 0x3 0x35 0x36>;
                        clock-names = "isp_top_core", "isp_top_axi", "noc_bus_isp_axi", "dvp_clk";
                        resets = <0x3 0x29 0x3 0x2a 0x3 0x1c>;
                        #clock-cells = <0x1>;
                        #reset-cells = <0x1>;
                        power-domains = <0x37 0x5>;
                        phandle = <0x32>;
                };
                phy@19820000 {

                        compatible = "starfive,jh7110-dphy-rx";
                        reg = <0x0 0x19820000 0x0 0x10000>;
                        clocks = <0x32 0x3 0x32 0x4 0x32 0x5>;
                        clock-names = "cfg", "ref", "tx";
                        resets = <0x32 0x2 0x32 0x3>;
                        power-domains = <0x2c 0x1>;
                        #phy-cells = <0x0>;
                        phandle = <0x33>;
                };
                camss@19840000 {

                        compatible = "starfive,jh7110-camss";
                        reg = <0x0 0x19840000 0x0 0x10000 0x0 0x19870000 0x0 0x30000>;
                        reg-names = "syscon", "isp";
                        clocks = <0x32 0x0 0x32 0xd 0x32 0x2 0x32 0xc 0x32 0x1 0x3 0x33 0x3 0x34>;
                        clock-names = "clk_apb_func", "clk_wrapper_clk_c", "clk_dvp_inv", "clk_axiwr", "clk_mipi_rx0_pxl", "clk_ispcore_2x", "clk_isp_axi";
                        resets = <0x32 0x0 0x32 0x1 0x32 0xa 0x32 0xb 0x3 0x29 0x3 0x2a>;
                        reset-names = "rst_wrapper_p", "rst_wrapper_c", "rst_axird", "rst_axiwr", "rst_isp_top_n", "rst_isp_top_axi";
                        power-domains = <0x37 0x5>;
                        interrupts = <0x5c 0x57 0x5a>;
                        status = "okay";
                        ports {

                                #address-cells = <0x1>;
                                #size-cells = <0x0>;
                                port@1 {

                                        reg = <0x1>;
                                        #address-cells = <0x1>;
                                        #size-cells = <0x0>;
                                        endpoint@1 {

                                                reg = <0x1>;
                                                remote-endpoint = <0x38>;
                                                status = "okay";
                                                phandle = <0x35>;
                                        };
                                };
                        };
                };
                clock-controller@295c0000 {

                        compatible = "starfive,jh7110-voutcrg";
                        reg = <0x0 0x295c0000 0x0 0x10000>;
                        clocks = <0x3 0x3a 0x3 0x3d 0x3 0x3e 0x3 0x3f 0x3 0xa5 0x39>;
                        clock-names = "vout_src", "vout_top_ahb", "vout_top_axi", "vout_top_hdmitx0_mclk", "i2stx0_bclk", "hdmitx0_pixelclk";
                        resets = <0x3 0x2b>;
                        #clock-cells = <0x1>;
                        #reset-cells = <0x1>;
                        power-domains = <0x37 0x4>;
                };
                pcie@2B000000 {

                        compatible = "starfive,jh7110-pcie";
                        #address-cells = <0x3>;
                        #size-cells = <0x2>;
                        #interrupt-cells = <0x1>;
                        reg = <0x0 0x2b000000 0x0 0x1000000 0x9 0x40000000 0x0 0x10000000>;
                        reg-names = "reg", "config";
                        device_type = "pci";
                        starfive,stg-syscon = <0x16 0xc0 0xc4 0x130 0x1b8>;
                        bus-range = <0x0 0xff>;
                        ranges = <0x82000000 0x0 0x30000000 0x0 0x30000000 0x0 0x8000000 0xc3000000 0x9 0x0 0x9 0x0 0x0 0x40000000>;
                        interrupts = <0x38>;
                        interrupt-parent = <0xa>;
                        interrupt-map-mask = <0x0 0x0 0x0 0x7>;
                        interrupt-map = <0x0 0x0 0x0 0x1 0x3a 0x1 0x0 0x0 0x0 0x2 0x3a 0x2 0x0 0x0 0x0 0x3 0x3a 0x3 0x0 0x0 0x0 0x4 0x3a 0x4>;
                        msi-parent = <0x3b>;
                        msi-controller;
                        clocks = <0x3 0x60 0x17 0xa 0x17 0x8 0x17 0x9>;
                        clock-names = "noc", "tl", "axi_mst0", "apb";
                        resets = <0x17 0xb 0x17 0xc 0x17 0xd 0x17 0xe 0x17 0xf 0x17 0x10>;
                        reset-names = "mst0", "slv0", "slv", "brg", "core", "apb";
                        status = "okay";
                        pinctrl-names = "default";
                        reset-gpios = <0x1d 0x1a 0x1>;
                        phys = <0x3c>;
                        phandle = <0x3b>;
                        interrupt-controller {

                                #address-cells = <0x0>;
                                #interrupt-cells = <0x1>;
                                interrupt-controller;
                                phandle = <0x3a>;
                        };
                };
                pcie@2C000000 {

                        compatible = "starfive,jh7110-pcie";
                        #address-cells = <0x3>;
                        #size-cells = <0x2>;
                        #interrupt-cells = <0x1>;
                        reg = <0x0 0x2c000000 0x0 0x1000000 0x9 0xc0000000 0x0 0x10000000>;
                        reg-names = "reg", "config";
                        device_type = "pci";
                        starfive,stg-syscon = <0x16 0x270 0x274 0x2e0 0x368>;
                        bus-range = <0x0 0xff>;
                        ranges = <0x82000000 0x0 0x38000000 0x0 0x38000000 0x0 0x8000000 0xc3000000 0x9 0x80000000 0x9 0x80000000 0x0 0x40000000>;
                        interrupts = <0x39>;
                        interrupt-parent = <0xa>;
                        interrupt-map-mask = <0x0 0x0 0x0 0x7>;
                        interrupt-map = <0x0 0x0 0x0 0x1 0x3d 0x1 0x0 0x0 0x0 0x2 0x3d 0x2 0x0 0x0 0x0 0x3 0x3d 0x3 0x0 0x0 0x0 0x4 0x3d 0x4>;
                        msi-parent = <0x3e>;
                        msi-controller;
                        clocks = <0x3 0x60 0x17 0xd 0x17 0xb 0x17 0xc>;
                        clock-names = "noc", "tl", "axi_mst0", "apb";
                        resets = <0x17 0x11 0x17 0x12 0x17 0x13 0x17 0x14 0x17 0x15 0x17 0x16>;
                        reset-names = "mst0", "slv0", "slv", "brg", "core", "apb";
                        status = "okay";
                        pinctrl-names = "default";
                        reset-gpios = <0x1d 0x1c 0x1>;
                        phys = <0x3f>;
                        phandle = <0x3e>;
                        interrupt-controller {

                                #address-cells = <0x0>;
                                #interrupt-cells = <0x1>;
                                interrupt-controller;
                                phandle = <0x3d>;
                        };
                };
        };
        aliases {

                ethernet0 = "/soc/ethernet@16030000";
                ethernet1 = "/soc/ethernet@16040000";
                i2c0 = "/soc/i2c@10030000";
                i2c2 = "/soc/i2c@10050000";
                i2c5 = "/soc/i2c@12050000";
                i2c6 = "/soc/i2c@12060000";
                serial0 = "/soc/serial@10000000";
        };
        chosen {

                fixup-applied;
                boot-hartid = <0x1>;
                bootargs = "console=ttyS0,115200  debug rootwait  earlycon=sbi";
                stdout-path = "serial0:115200n8";
        };
        memory@40000000 {

                device_type = "memory";
                reg = <0x0 0x40000000 0x1 0x0>;
        };
        reserved-memory {

                #address-cells = <0x2>;
                #size-cells = <0x2>;
                ranges;
                opensbi@40000000 {

                        no-map;
                        reg = <0x0 0x40000000 0x0 0x80000>;
                        phandle = <0x41>;
                };
                linux,cma {

                        compatible = "shared-dma-pool";
                        reusable;
                        size = <0x0 0x20000000>;
                        alignment = <0x0 0x1000>;
                        alloc-ranges = <0x0 0x80000000 0x0 0x20000000>;
                        linux,cma-default;
                };
        };
        thermal-zones {

                cpu-thermal {

                        polling-delay-passive = <0xfa>;
                        polling-delay = <0x3a98>;
                        thermal-sensors = <0x40>;
                        cooling-maps {

                        };
                        trips {

                                cpu_alert0 {

                                        temperature = <0x124f8>;
                                        hysteresis = <0x7d0>;
                                        type = "passive";
                                };
                                cpu_crit {

                                        temperature = <0x15f90>;
                                        hysteresis = <0x7d0>;
                                        type = "critical";
                                };
                        };
                };
        };
        gpio-restart {

                compatible = "gpio-restart";
                gpios = <0x1d 0x23 0x0>;
                priority = <0xe0>;
        };
        clk_ext_camera {

                compatible = "fixed-clock";
                #clock-cells = <0x0>;
                clock-frequency = <0x16e3600>;
                phandle = <0x1c>;
        };
};

